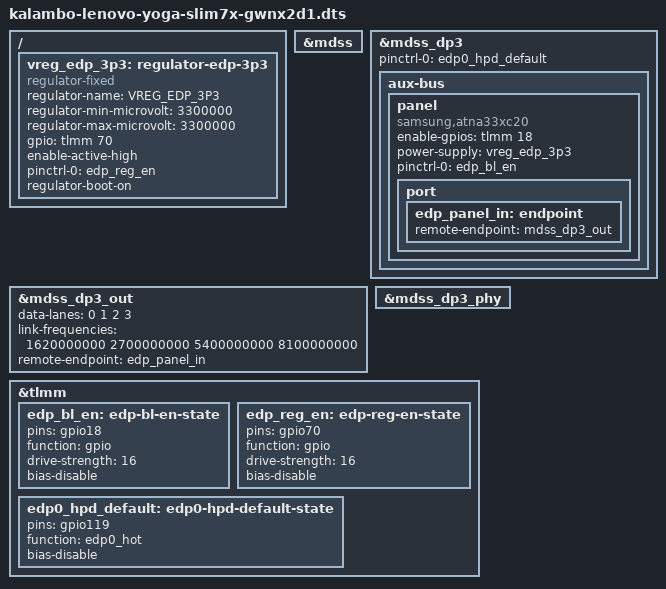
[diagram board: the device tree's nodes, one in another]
// SPDX-License-Identifier: BSD-3-Clause
/*
 * gwnxd1 = gwnx1 (slot current: bateria/pmic-glink, Bluetooth, toque, EC-bus,
 * cpufreq, USB2 host, ADSP) + os nos de video do gwnd1 (MDSS/DPU, mdss_dp3,
 * PHY eDP, painel OLED, 3,3 V do painel, pinos 18/70/119). Uso diario do
 * video real. A composicao e conferida por diff estrutural contra os dois
 * pais: gwnxd1 - gwnx1 == gwnd1 - gwn1, nada mais.
 *
 * O bloco de video abaixo e COPIA LITERAL de
 * kalambo-lenovo-yoga-slim7x-gwnd1.dts:48-142 (validado no hardware no teste
 * T2 de 2026-11-16: link HBR2 x2, imagem, brilho por dp_aux_backlight). Nao
 * da para incluir o gwnd1: ele e o gwnx1 incluem o gwn1, e o DTS nao tem
 * guarda de inclusao. As fontes de cada no (REF, T14S, DSDT, HW) estao no
 * cabecalho do gwnd1; mudou la, repita aqui.
 *
 * So funciona com o PHY corrigido (local/iso-build/extmod-edp3 ou
 * local/dtb-bisect-r5/phy-qcom-edp-glymur-pll-v2.patch): com o phy-qcom-edp
 * da arvore o link nao fecha, e so com a correcao do PLL fecha a 30 Hz com a
 * tela preta. Por isso o slot bloqueia phy_qcom_edp na cmdline (o initramfs
 * tem o da arvore) e o yoga-video.service carrega o de updates/ pelo nome.
 *
 * simple-framebuffer (g1) FICA: da console no boot e e o plano B se o
 * servico de video abortar antes de carregar o msm. A troca e feita pelo
 * proprio msm: msm_drm_kms_init() chama
 * aperture_remove_all_conflicting_devices() (msm_kms.c:272) e o simpledrm sai
 * (T2: "Console: switching to colour dummy device" e depois "fb0:
 * msm-kmsdrmfb"; o msm fica como card1). O msm tem de estar de pe ANTES do
 * GDM, senao o mutter perde o card0 no meio da sessao.
 *
 * GPU: &gpu/&gmu ficam como no gwnx1 (habilitados por heranca). Com um GPU e
 * um MDSS o msm junta os dois num unico dispositivo DRM e o display esperaria
 * a GPU, que nao sobe com gpucc_glymur bloqueado (msm_drv.c:113-137); por isso
 * o msm e carregado com separate_gpu_kms=1, como no T2.
 *
 * regulator_ignore_unused continua obrigatorio na cmdline (ver abaixo).
 */

#include "kalambo-lenovo-yoga-slim7x-gwnx2.dts"

/ {
	/*
	 * REF:176-190, identico. Sem regulator-always-on de proposito: o painel
	 * exige ciclo de energia depois que EL_ON3 cai
	 * (panel-samsung-atna33xc20.c:168-176). regulator-boot-on faz o GPIO
	 * ser pedido ja em nivel alto (fixed.c:299), igual ao que o firmware
	 * deixou. Enquanto o driver do painel nao existir, quem impede o
	 * desligamento aos 30 s e o regulator_ignore_unused da cmdline
	 * (regulator/core.c:6872): NAO remover esse parametro com este DTB.
	 */
	vreg_edp_3p3: regulator-edp-3p3 {
		compatible = "regulator-fixed";

		regulator-name = "VREG_EDP_3P3";
		regulator-min-microvolt = <3300000>;
		regulator-max-microvolt = <3300000>;

		gpio = <&tlmm 70 GPIO_ACTIVE_HIGH>;
		enable-active-high;

		pinctrl-0 = <&edp_reg_en>;
		pinctrl-names = "default";

		regulator-boot-on;
	};
};

/* REF:501-503 */
&mdss {
	status = "okay";
};

/* REF:529-550; pinctrl do HPD como no T14S:574-575 */
&mdss_dp3 {
	/delete-property/ #sound-dai-cells;

	pinctrl-0 = <&edp0_hpd_default>;
	pinctrl-names = "default";

	status = "okay";

	aux-bus {
		panel {
			compatible = "samsung,atna33xc20";
			enable-gpios = <&tlmm 18 GPIO_ACTIVE_HIGH>;
			power-supply = <&vreg_edp_3p3>;

			pinctrl-0 = <&edp_bl_en>;
			pinctrl-names = "default";

			port {
				edp_panel_in: endpoint {
					remote-endpoint = <&mdss_dp3_out>;
				};
			};
		};
	};
};

/* REF:552-557 */
&mdss_dp3_out {
	data-lanes = <0 1 2 3>;
	link-frequencies = /bits/ 64 <1620000000 2700000000 5400000000 8100000000>;

	remote-endpoint = <&edp_panel_in>;
};

/* Supplies herdados: vdda-phy = l2f1, vdda-pll = l4f1 (glymur-cob.dtsi:199-202). REF:559-561 */
&mdss_dp3_phy {
	status = "okay";
};

&tlmm {
	/* REF:753-758 */
	edp_bl_en: edp-bl-en-state {
		pins = "gpio18";
		function = "gpio";
		drive-strength = <16>;
		bias-disable;
	};

	/* REF:787-792 */
	edp_reg_en: edp-reg-en-state {
		pins = "gpio70";
		function = "gpio";
		drive-strength = <16>;
		bias-disable;
	};

	/* T14S:773-777; repete o que o firmware deixou */
	edp0_hpd_default: edp0-hpd-default-state {
		pins = "gpio119";
		function = "edp0_hot";
		bias-disable;
	};
};
